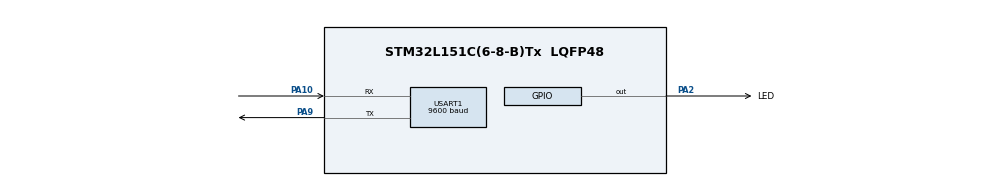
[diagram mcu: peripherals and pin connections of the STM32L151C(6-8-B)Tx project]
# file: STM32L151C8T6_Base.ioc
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Mcu.Family=STM32L1
Mcu.Name=STM32L151C(6-8-B)Tx
Mcu.Package=LQFP48
NVIC.PriorityGroup=NVIC_PRIORITYGROUP_4
PA10.Mode=Asynchronous
PA10.Signal=USART1_RX
PA2.GPIO_Label=LED
PA2.Signal=GPIO_Output
PA9.Mode=Asynchronous
PA9.Signal=USART1_TX
PC14-OSC32_IN.Mode=LSE-External-Oscillator
PC14-OSC32_IN.Signal=RCC_OSC32_IN
PC15-OSC32_OUT.Mode=LSE-External-Oscillator
PC15-OSC32_OUT.Signal=RCC_OSC32_OUT
PH0-OSC_IN.Mode=HSE-External-Oscillator
PH0-OSC_IN.Signal=RCC_OSC_IN
PH1-OSC_OUT.Mode=HSE-External-Oscillator
PH1-OSC_OUT.Signal=RCC_OSC_OUT
ProjectManager.HeapSize=0x200
ProjectManager.StackSize=0x400
ProjectManager.TargetToolchain=EWARM V8.32
RCC.48MHZClocksFreq_Value=32000000
RCC.AHBFreq_Value=32000000
RCC.APB1Freq_Value=32000000
RCC.APB1TimFreq_Value=32000000
RCC.APB2Freq_Value=32000000
RCC.APB2TimFreq_Value=32000000
RCC.HCLKFreq_Value=32000000
RCC.HSE_VALUE=16000000
RCC.HSI_VALUE=16000000
RCC.MSI_VALUE=2097000
RCC.PLLMUL=RCC_PLL_MUL4
RCC.PLLSourceVirtual=RCC_PLLSOURCE_HSE
RCC.SYSCLKFreq_VALUE=32000000
RCC.SYSCLKSource=RCC_SYSCLKSOURCE_PLLCLK
RCC.VCOOutputFreq_Value=64000000
USART1.BaudRate=9600
USART1.VirtualMode=VM_ASYNC
board=custom

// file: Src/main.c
/* USER CODE BEGIN Header */
/**
  ******************************************************************************
  * @file           : main.c
  * @brief          : Main program body
  ******************************************************************************
  * @attention
  *
  * <h2><center>&copy; Copyright (c) 2020 STMicroelectronics.
  * All rights reserved.</center></h2>
  *
  * This software component is licensed by ST under BSD 3-Clause license,
  * the "License"; You may not use this file except in compliance with the
  * License. You may obtain a copy of the License at:
  *                        opensource.org/licenses/BSD-3-Clause
  *
  ******************************************************************************
  */
/* USER CODE END Header */

#include "main.h"

void SystemClock_Config(void);
static void MX_GPIO_Init(void);
static void MX_USART1_UART_Init(void);

int main(void)
{

  /* MCU Configuration--------------------------------------------------------*/

  /* Reset of all peripherals, Initializes the Flash interface and the Systick. */

  LL_APB1_GRP1_EnableClock(LL_APB1_GRP1_PERIPH_COMP);
  LL_APB2_GRP1_EnableClock(LL_APB2_GRP1_PERIPH_SYSCFG);
  LL_APB1_GRP1_EnableClock(LL_APB1_GRP1_PERIPH_PWR);

  NVIC_SetPriorityGrouping(NVIC_PRIORITYGROUP_4);

  /* System interrupt init*/

  /* Configure the system clock */
  SystemClock_Config();

  /* Initialize all configured peripherals */
  MX_GPIO_Init();
  MX_USART1_UART_Init();

  /* Infinite loop */
  /* USER CODE BEGIN WHILE */
  while (1)
  {
    HAL_GPIO_WritePin(GPIOA,LED_Pin,GPIO_PIN_SET);
    HAL_GPIO_WritePin(GPIOA,LEDA3_Pin,GPIO_PIN_SET);
    HAL_GPIO_WritePin(GPIOB,LED_B3_Pin,GPIO_PIN_SET);
    HAL_GPIO_WritePin(GPIOB,LED_B4_Pin,GPIO_PIN_SET);
    HAL_UART_Transmit(&huart1,"Amit Chaudhary : ON\n\r",sizeof("Amit Chaudhary : ON\n\r")-1,10000);
    HAL_Delay(1000);
    HAL_GPIO_WritePin(GPIOA,LED_Pin,GPIO_PIN_RESET);
    HAL_GPIO_WritePin(GPIOA,LEDA3_Pin,GPIO_PIN_RESET);
    HAL_GPIO_WritePin(GPIOB,LED_B3_Pin,GPIO_PIN_RESET);
    HAL_GPIO_WritePin(GPIOB,LED_B4_Pin,GPIO_PIN_RESET);
    HAL_UART_Transmit(&huart1,"Amit Chaudhary : OFF\n\r",sizeof("Amit Chaudhary : OFF\n\r")-1,10000);
    HAL_Delay(1000);
    /* USER CODE END WHILE */

  }
}

void SystemClock_Config(void)
{

  LL_FLASH_Enable64bitAccess();

  LL_FLASH_SetLatency(LL_FLASH_LATENCY_1);

  if(LL_FLASH_GetLatency() != LL_FLASH_LATENCY_1)
  {
  Error_Handler();
  }
  LL_PWR_SetRegulVoltageScaling(LL_PWR_REGU_VOLTAGE_SCALE1);
  LL_RCC_HSE_Enable();

   /* Wait till HSE is ready */
  while(LL_RCC_HSE_IsReady() != 1)
  {

  }
  LL_RCC_PLL_ConfigDomain_SYS(LL_RCC_PLLSOURCE_HSE, LL_RCC_PLL_MUL_4, LL_RCC_PLL_DIV_2);
  LL_RCC_PLL_Enable();

   /* Wait till PLL is ready */
  while(LL_RCC_PLL_IsReady() != 1)
  {

  }
  LL_RCC_SetAHBPrescaler(LL_RCC_SYSCLK_DIV_1);
  LL_RCC_SetAPB1Prescaler(LL_RCC_APB1_DIV_1);
  LL_RCC_SetAPB2Prescaler(LL_RCC_APB2_DIV_1);
  LL_RCC_SetSysClkSource(LL_RCC_SYS_CLKSOURCE_PLL);

   /* Wait till System clock is ready */
  while(LL_RCC_GetSysClkSource() != LL_RCC_SYS_CLKSOURCE_STATUS_PLL)
  {

  }

  LL_Init1msTick(32000000);

  LL_SYSTICK_SetClkSource(LL_SYSTICK_CLKSOURCE_HCLK);
  LL_SetSystemCoreClock(32000000);
}

static void MX_USART1_UART_Init(void)
{

  LL_USART_InitTypeDef USART_InitStruct = {0};

  LL_GPIO_InitTypeDef GPIO_InitStruct = {0};

  /* Peripheral clock enable */
  LL_APB2_GRP1_EnableClock(LL_APB2_GRP1_PERIPH_USART1);

  LL_AHB1_GRP1_EnableClock(LL_AHB1_GRP1_PERIPH_GPIOA);
  /**USART1 GPIO Configuration
  PA9   ------> USART1_TX
  PA10   ------> USART1_RX
  */
  GPIO_InitStruct.Pin = LL_GPIO_PIN_9;
  GPIO_InitStruct.Mode = LL_GPIO_MODE_ALTERNATE;
  GPIO_InitStruct.Speed = LL_GPIO_SPEED_FREQ_VERY_HIGH;
  GPIO_InitStruct.OutputType = LL_GPIO_OUTPUT_PUSHPULL;
  GPIO_InitStruct.Pull = LL_GPIO_PULL_NO;
  GPIO_InitStruct.Alternate = LL_GPIO_AF_7;
  LL_GPIO_Init(GPIOA, &GPIO_InitStruct);

  GPIO_InitStruct.Pin = LL_GPIO_PIN_10;
  GPIO_InitStruct.Mode = LL_GPIO_MODE_ALTERNATE;
  GPIO_InitStruct.Speed = LL_GPIO_SPEED_FREQ_VERY_HIGH;
  GPIO_InitStruct.OutputType = LL_GPIO_OUTPUT_PUSHPULL;
  GPIO_InitStruct.Pull = LL_GPIO_PULL_NO;
  GPIO_InitStruct.Alternate = LL_GPIO_AF_7;
  LL_GPIO_Init(GPIOA, &GPIO_InitStruct);

  USART_InitStruct.BaudRate = 9600;
  USART_InitStruct.DataWidth = LL_USART_DATAWIDTH_8B;
  USART_InitStruct.StopBits = LL_USART_STOPBITS_1;
  USART_InitStruct.Parity = LL_USART_PARITY_NONE;
  USART_InitStruct.TransferDirection = LL_USART_DIRECTION_TX_RX;
  USART_InitStruct.HardwareFlowControl = LL_USART_HWCONTROL_NONE;
  USART_InitStruct.OverSampling = LL_USART_OVERSAMPLING_16;
  LL_USART_Init(USART1, &USART_InitStruct);
  LL_USART_DisableIT_CTS(USART1);
  LL_USART_ConfigAsyncMode(USART1);
  LL_USART_Enable(USART1);

}

static void MX_GPIO_Init(void)
{
  LL_GPIO_InitTypeDef GPIO_InitStruct = {0};

  /* GPIO Ports Clock Enable */
  LL_AHB1_GRP1_EnableClock(LL_AHB1_GRP1_PERIPH_GPIOC);
  LL_AHB1_GRP1_EnableClock(LL_AHB1_GRP1_PERIPH_GPIOH);
  LL_AHB1_GRP1_EnableClock(LL_AHB1_GRP1_PERIPH_GPIOA);

  /**/
  LL_GPIO_ResetOutputPin(LED_GPIO_Port, LED_Pin);

  /**/
  GPIO_InitStruct.Pin = LED_Pin;
  GPIO_InitStruct.Mode = LL_GPIO_MODE_OUTPUT;
  GPIO_InitStruct.Speed = LL_GPIO_SPEED_FREQ_LOW;
  GPIO_InitStruct.OutputType = LL_GPIO_OUTPUT_PUSHPULL;
  GPIO_InitStruct.Pull = LL_GPIO_PULL_NO;
  LL_GPIO_Init(LED_GPIO_Port, &GPIO_InitStruct);

}

void Error_Handler(void)
{
}

/************************ (C) COPYRIGHT STMicroelectronics *****END OF FILE****/
